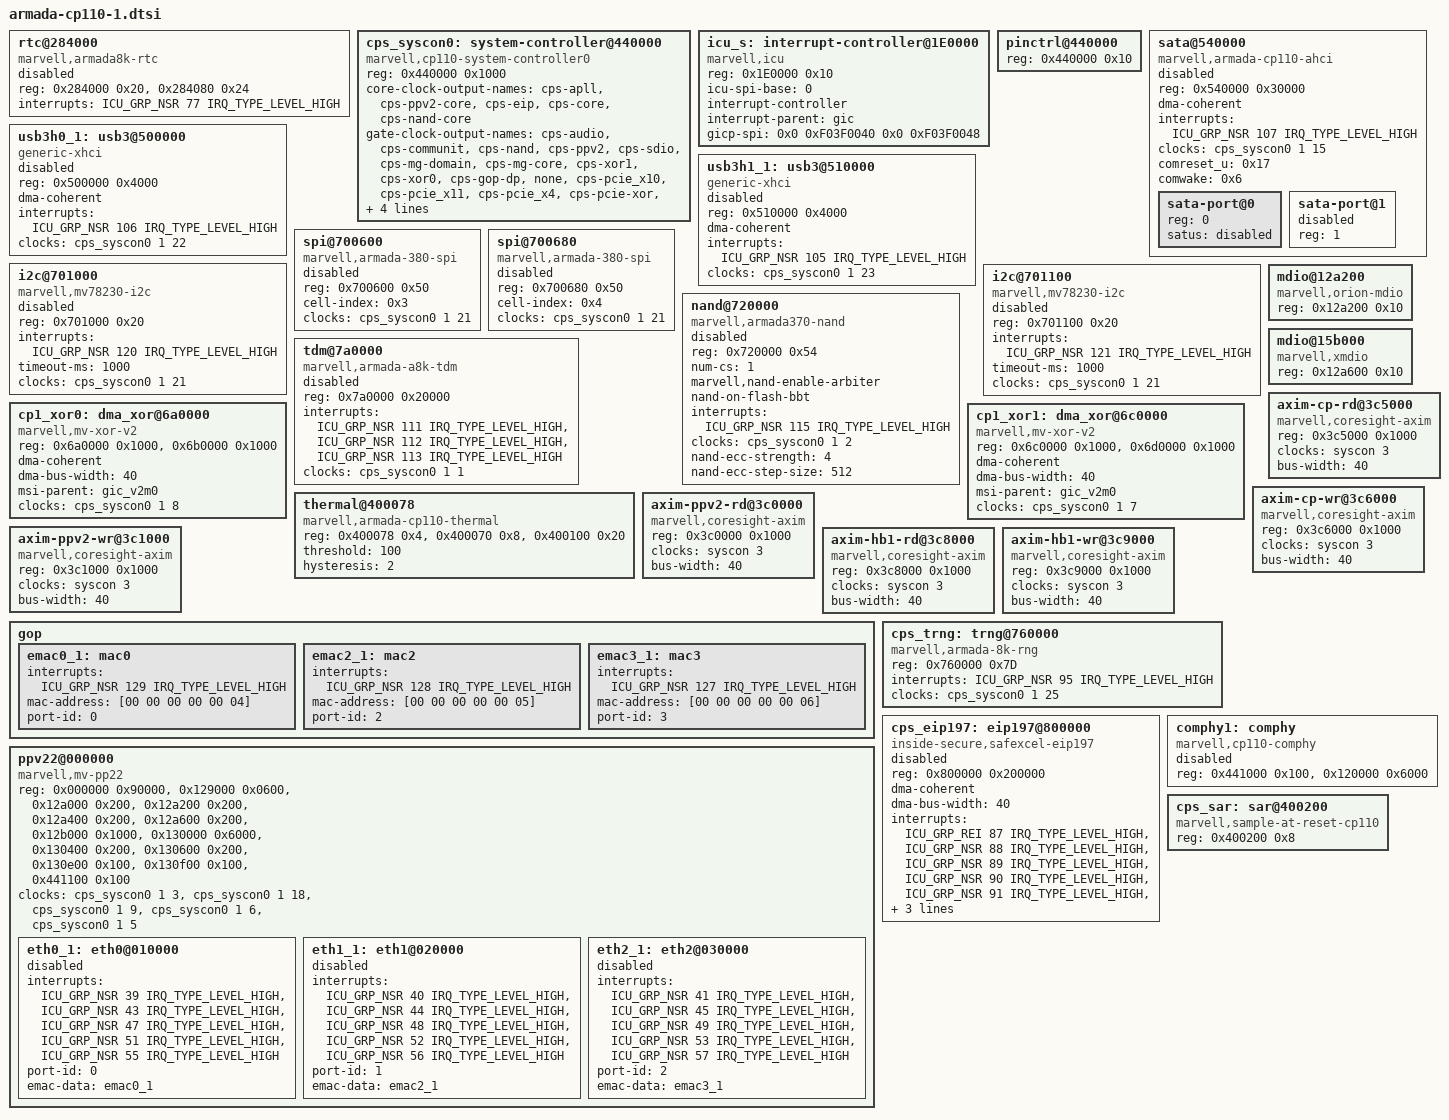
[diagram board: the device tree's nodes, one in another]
/****************************************************************************
* This program is free software: you can redistribute it and/or modify it
* under the terms of the GNU General Public License as published by the Free
* Software Foundation, either version 2 of the License, or any later version.
*
* This program is distributed in the hope that it will be useful,
* but WITHOUT ANY WARRANTY; without even the implied warranty of
* MERCHANTABILITY or FITNESS FOR A PARTICULAR PURPOSE.  See the
* GNU General Public License for more details.
*
* You should have received a copy of the GNU General Public License
* along with this program.  If not, see <http://www.gnu.org/licenses/>.
* ***************************************************************************
*/

/*
 * Generic Device Tree describing Marvell Armada CP-110 device
 */
#include <dt-bindings/interrupt-controller/mvebu-icu.h>

rtc@284000 {
	compatible = "marvell,armada8k-rtc";
	reg = <0x284000 0x20>, <0x284080 0x24>;
	reg-names = "rtc", "rtc-soc";
	#address-cells = <1>;
	#size-cells = <0>;
	interrupts = <ICU_GRP_NSR 77 IRQ_TYPE_LEVEL_HIGH>;
	status = "disabled";
};

cps_syscon0: system-controller@440000 {
	compatible = "marvell,cp110-system-controller0",
		     "syscon";
	reg = <0x440000 0x1000>;
	#clock-cells = <2>;
	core-clock-output-names =
		"cps-apll", "cps-ppv2-core", "cps-eip",
		"cps-core", "cps-nand-core";
	gate-clock-output-names =
		"cps-audio", "cps-communit", "cps-nand",
		"cps-ppv2", "cps-sdio", "cps-mg-domain",
		"cps-mg-core", "cps-xor1", "cps-xor0",
		"cps-gop-dp", "none", "cps-pcie_x10",
		"cps-pcie_x11", "cps-pcie_x4", "cps-pcie-xor",
		"cps-sata", "cps-sata-usb", "cps-main",
		"cps-sd-mmc", "none", "none",
		"cps-slow-io", "cps-usb3h0", "cps-usb3h1",
		"cps-usb3dev", "cps-eip150", "cps-eip197";
};

icu_s: interrupt-controller@1E0000 {
	compatible = "marvell,icu";
	reg = <0x1E0000 0x10>;
	#interrupt-cells = <3>;
	#size-cells = <1>;
	#address-cells = <0>;
	icu-spi-base = <0>;
	interrupt-controller;
	interrupt-parent = <&gic>;
	gicp-spi = <0x0 0xF03F0040 0x0 0xF03F0048>;
};
pinctrl@440000 {
	reg = <0x440000 0x10>;
};

sata@540000 {
	compatible = "marvell,armada-cp110-ahci";
	reg = <0x540000 0x30000>;
	dma-coherent;
	interrupts = <ICU_GRP_NSR 107 IRQ_TYPE_LEVEL_HIGH>;
	clocks = <&cps_syscon0 1 15>;
	status = "disabled";
	comreset_u = <0x17>;
	comwake = <0x6>;
	#address-cells = <1>;
	#size-cells = <0>;

	sata-port@0 {
		reg = <0>;
		satus = "disabled";
	};
	sata-port@1 {
		reg = <1>;
		status = "disabled";
	};
};

usb3h0_1: usb3@500000 {
	compatible = "generic-xhci";
	reg = <0x500000 0x4000>;
	dma-coherent;
	interrupts = <ICU_GRP_NSR 106 IRQ_TYPE_LEVEL_HIGH>;
	clocks = <&cps_syscon0 1 22>;
	status = "disabled";
};

usb3h1_1: usb3@510000 {
	compatible = "generic-xhci";
	reg = <0x510000 0x4000>;
	dma-coherent;
	interrupts = <ICU_GRP_NSR 105 IRQ_TYPE_LEVEL_HIGH>;
	clocks = <&cps_syscon0 1 23>;
	status = "disabled";
};

spi@700600 {
	compatible = "marvell,armada-380-spi";
	reg = <0x700600 0x50>;
	#address-cells = <0x1>;
	#size-cells = <0x0>;
	cell-index = <0x3>;
	clocks = <&cps_syscon0 1 21>;
	status = "disabled";
};

spi@700680 {
	compatible = "marvell,armada-380-spi";
	reg = <0x700680 0x50>;
	#address-cells = <0x1>;
	#size-cells = <0x0>;
	cell-index = <0x4>;
	clocks = <&cps_syscon0 1 21>;
	status = "disabled";
};

i2c@701000 {
	compatible = "marvell,mv78230-i2c";
	reg = <0x701000 0x20>;
	#address-cells = <1>;
	#size-cells = <0>;
	interrupts = <ICU_GRP_NSR 120 IRQ_TYPE_LEVEL_HIGH>;
	timeout-ms = <1000>;
	clocks = <&cps_syscon0 1 21>;
	status = "disabled";
};

i2c@701100 {
	compatible = "marvell,mv78230-i2c";
	reg = <0x701100 0x20>;
	#address-cells = <1>;
	#size-cells = <0>;
	interrupts = <ICU_GRP_NSR 121 IRQ_TYPE_LEVEL_HIGH>;
	timeout-ms = <1000>;
	clocks = <&cps_syscon0 1 21>;
	status = "disabled";
};

nand@720000 {
	compatible = "marvell,armada370-nand";
	reg = <0x720000 0x54>;
	#address-cells = <1>;
	#size-cells = <1>;
	num-cs = <1>;
	marvell,nand-enable-arbiter;
	nand-on-flash-bbt;
	interrupts = <ICU_GRP_NSR 115 IRQ_TYPE_LEVEL_HIGH>;
	clocks = <&cps_syscon0 1 2>;
	nand-ecc-strength = <4>;
	nand-ecc-step-size = <512>;
	status = "disabled";
};

tdm@7a0000 {
	compatible = "marvell,armada-a8k-tdm";
	reg = <0x7a0000 0x20000>;
	reg-names = "tdm_regs";
	interrupts = <ICU_GRP_NSR 111 IRQ_TYPE_LEVEL_HIGH>,
		     <ICU_GRP_NSR 112 IRQ_TYPE_LEVEL_HIGH>,
		     <ICU_GRP_NSR 113 IRQ_TYPE_LEVEL_HIGH>;
	clocks = <&cps_syscon0 1 1>;
	clock-names = "gateclk";
	status = "disabled";
};

cp1_xor0: dma_xor@6a0000 {
	compatible = "marvell,mv-xor-v2";
	reg = <0x6a0000 0x1000>,
	      <0x6b0000 0x1000>;
	dma-coherent;
	dma-bus-width = <40>;
	msi-parent = <&gic_v2m0>;
	clocks = <&cps_syscon0 1 8>;
	status = "okay";
};

cp1_xor1: dma_xor@6c0000 {
	compatible = "marvell,mv-xor-v2";
	reg = <0x6c0000 0x1000>,
	      <0x6d0000 0x1000>;
	dma-coherent;
	dma-bus-width = <40>;
	msi-parent = <&gic_v2m0>;
	clocks = <&cps_syscon0 1 7>;
	status = "okay";
};

thermal@400078 {
	compatible = "marvell,armada-cp110-thermal";
	reg = <0x400078 0x4>,
		<0x400070 0x8>,
		<0x400100 0x20>;
	/* interrupt assignment by ICU supports single thermal sensor unit,
	 * currently cp0 thermal sensor irq is enabled.
	 * To enable cp1 thermal sensor interrupt,
	 * first disable cp0 thermal sensor interrupt.
	 */
	/* interrupts-extended = <&sei 37>;*/
	threshold = <100>;
	hysteresis = <2>;
	status = "okay";
};

mdio@12a200 {
	#address-cells = <1>;
	#size-cells = <0>;
	compatible = "marvell,orion-mdio";
	reg = <0x12a200 0x10>;
};

mdio@15b000 {
	#address-cells = <1>;
	#size-cells = <0>;
	compatible = "marvell,xmdio";
	reg = <0x12a600 0x10>;
};

axim-cp-rd@3c5000 {
	compatible = "marvell,coresight-axim", "arm,primecell";
	reg = <0x3c5000 0x1000>;
	clocks = <&syscon 3>;
	clock-names = "apb_pclk";
	bus-width = <40>;
};

axim-cp-wr@3c6000 {
	compatible = "marvell,coresight-axim", "arm,primecell";
	reg = <0x3c6000 0x1000>;
	clocks = <&syscon 3>;
	clock-names = "apb_pclk";
	bus-width = <40>;
};

axim-ppv2-rd@3c0000 {
	compatible = "marvell,coresight-axim", "arm,primecell";
	reg = <0x3c0000 0x1000>;
	clocks = <&syscon 3>;
	clock-names = "apb_pclk";
	bus-width = <40>;
};

axim-ppv2-wr@3c1000 {
	compatible = "marvell,coresight-axim", "arm,primecell";
	reg = <0x3c1000 0x1000>;
	clocks = <&syscon 3>;
	clock-names = "apb_pclk";
	bus-width = <40>;
};

axim-hb1-rd@3c8000 {
	compatible = "marvell,coresight-axim", "arm,primecell";
	reg = <0x3c8000 0x1000>;
	clocks = <&syscon 3>;
	clock-names = "apb_pclk";
	bus-width = <40>;
};

axim-hb1-wr@3c9000 {
	compatible = "marvell,coresight-axim", "arm,primecell";
	reg = <0x3c9000 0x1000>;
	clocks = <&syscon 3>;
	clock-names = "apb_pclk";
	bus-width = <40>;
};

gop {
	emac0_1: mac0 {
		interrupts = <ICU_GRP_NSR 129 IRQ_TYPE_LEVEL_HIGH>;  /* Link IRQ */
		mac-address = [00 00 00 00 00 04];
		port-id = <0>; /* gop_port_id */
	};
	emac2_1: mac2 {
		interrupts = <ICU_GRP_NSR 128 IRQ_TYPE_LEVEL_HIGH>;  /* Link IRQ */
		mac-address = [00 00 00 00 00 05];
		port-id = <2>; /* gop_port_id */
	};
	emac3_1: mac3 {
		interrupts = <ICU_GRP_NSR 127 IRQ_TYPE_LEVEL_HIGH>;  /* Link IRQ */
		mac-address = [00 00 00 00 00 06];
		port-id = <3>; /* gop_port_id */
	};
};

ppv22@000000 {
	compatible = "marvell,mv-pp22";
	reg = <0x000000 0x90000>, /* Packet Processor regs */
	      <0x129000 0x0600>, /* XMIB regs */
	      <0x12a000 0x200>,  /* LED regs */
	      <0x12a200 0x200>,  /* SMI regs */
	      <0x12a400 0x200>,  /* TAI regs */
	      <0x12a600 0x200>,  /* XSMI regs */
	      <0x12b000 0x1000>,  /* MG Internal regs */
	      <0x130000 0x6000>, /* MSPG regs */
	      <0x130400 0x200>,  /* MSPG - XPCS regs */
	      <0x130600 0x200>,  /* FCA - flow control regs*/
	      <0x130e00 0x100>,  /* MSPG - GMAC regs */
	      <0x130f00 0x100>,  /* MSPG - XLG MAC regs */
	      <0x441100 0x100>;  /* RFU-1 Regs */
	reg-names = "pp", "xmib", "led", "smi", "tai", "xsmi", "mg", "mspg", "xpcs",
		    "fca", "gmac", "xlg", "rfu1";
	clocks = <&cps_syscon0 1 3>, <&cps_syscon0 1 18>, <&cps_syscon0 1 9>,
		 <&cps_syscon0 1 6>, <&cps_syscon0 1 5>;
	clock-names = "pp_clk", "gop_core_clk", "gop_clk", "mg_core_clk", "mg_clk";
	status = "okay";
	eth0_1: eth0@010000 {
		interrupts = <ICU_GRP_NSR 39 IRQ_TYPE_LEVEL_HIGH>, /* TX CPU#0 Interrupt */
			     <ICU_GRP_NSR 43 IRQ_TYPE_LEVEL_HIGH>, /* TX CPU#1 Interrupt */
			     <ICU_GRP_NSR 47 IRQ_TYPE_LEVEL_HIGH>, /* TX CPU#2 Interrupt */
			     <ICU_GRP_NSR 51 IRQ_TYPE_LEVEL_HIGH>, /* TX CPU#3 Interrupt */
			     <ICU_GRP_NSR 55 IRQ_TYPE_LEVEL_HIGH>; /* RX Shared Interrupt */
		port-id = <0>; /* pp2_port_id */
		emac-data = <&emac0_1>;
		status = "disabled";
	};
	eth1_1: eth1@020000 {
		interrupts = <ICU_GRP_NSR 40 IRQ_TYPE_LEVEL_HIGH>, /* TX CPU#0 Interrupt */
			     <ICU_GRP_NSR 44 IRQ_TYPE_LEVEL_HIGH>, /* TX CPU#1 Interrupt */
			     <ICU_GRP_NSR 48 IRQ_TYPE_LEVEL_HIGH>, /* TX CPU#2 Interrupt */
			     <ICU_GRP_NSR 52 IRQ_TYPE_LEVEL_HIGH>, /* TX CPU#3 Interrupt */
			     <ICU_GRP_NSR 56 IRQ_TYPE_LEVEL_HIGH>; /* RX Shared Interrupt */
		port-id = <1>; /* pp2_port_id */
		emac-data = <&emac2_1>;
		status = "disabled";
	};
	eth2_1: eth2@030000 {
		interrupts = <ICU_GRP_NSR 41 IRQ_TYPE_LEVEL_HIGH>, /* TX CPU#0 Interrupt */
			     <ICU_GRP_NSR 45 IRQ_TYPE_LEVEL_HIGH>, /* TX CPU#1 Interrupt */
			     <ICU_GRP_NSR 49 IRQ_TYPE_LEVEL_HIGH>, /* TX CPU#2 Interrupt */
			     <ICU_GRP_NSR 53 IRQ_TYPE_LEVEL_HIGH>, /* TX CPU#3 Interrupt */
			     <ICU_GRP_NSR 57 IRQ_TYPE_LEVEL_HIGH>; /* RX Shared Interrupt */
		port-id = <2>; /* pp2_port_id */
		emac-data = <&emac3_1>;
		status = "disabled";
	};
};

cps_trng: trng@760000 {
	compatible = "marvell,armada-8k-rng", "inside-secure,safexcel-eip76";
	reg = <0x760000 0x7D>;
	#address-cells = <1>;
	#size-cells = <0>;
	interrupts = <ICU_GRP_NSR 95 IRQ_TYPE_LEVEL_HIGH>;
	clocks = <&cps_syscon0 1 25>;
	status = "okay";
};

cps_eip197: eip197@800000 {
	compatible = "inside-secure,safexcel-eip197";
	reg = <0x800000 0x200000>;
	dma-coherent;
	dma-bus-width = <40>;
	interrupts = <ICU_GRP_REI 87 IRQ_TYPE_LEVEL_HIGH>,
		     <ICU_GRP_NSR 88 IRQ_TYPE_LEVEL_HIGH>,
		     <ICU_GRP_NSR 89 IRQ_TYPE_LEVEL_HIGH>,
		     <ICU_GRP_NSR 90 IRQ_TYPE_LEVEL_HIGH>,
		     <ICU_GRP_NSR 91 IRQ_TYPE_LEVEL_HIGH>,
		     <ICU_GRP_NSR 92 IRQ_TYPE_LEVEL_HIGH>;
	interrupt-names = "eip_addr", "ring0", "ring1",
			  "ring2", "ring3", "eip_out";
	clocks = <&cps_syscon0 1 26>;
	cell-index = <1>;
	status = "disabled";
};

comphy1: comphy {
	compatible = "marvell,cp110-comphy";
	reg = <0x441000 0x100>, <0x120000 0x6000>;
	reg-names = "comphy", "serdes";
	#phy-cells = <2>;
	status = "disabled";
};

cps_sar: sar@400200 {
	compatible = "marvell,sample-at-reset-cp110";
	reg = <0x400200 0x8>;
	status = "okay";
};
